# ipro7 register map
Vendor: intelpro; Series: BTBLE
CPU: ipro7, little endian
Registers are 32-bit, read-write, reset 0x0 unless marked. A register's access mark holds for its fields unless they carry their own. Offsets are from the block's base; [hi:lo] are bit positions.

## OSD_BLEND
Base 0x30046000
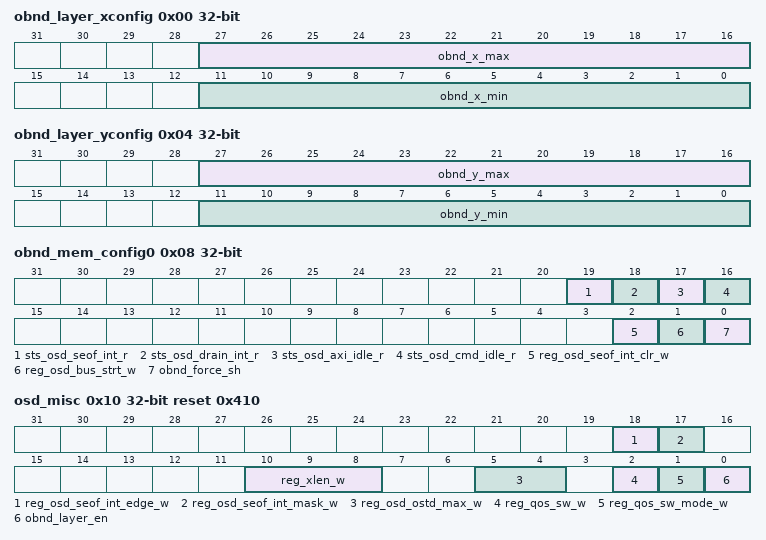
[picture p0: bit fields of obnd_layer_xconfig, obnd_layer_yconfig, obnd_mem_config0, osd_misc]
0x00 obnd_layer_xconfig
  [27:16] obnd_x_max — Start X point of blend layer
  [11:0] obnd_x_min — End X point of blend layer
0x04 obnd_layer_yconfig
  [27:16] obnd_y_max — Start Y point of blend layer
  [11:0] obnd_y_min — End Y point of blend layer
0x08 obnd_mem_config0 (reset mask 0xFFF0FFFF)
  [19] sts_osd_seof_int_r ro — Osd s/e-of status
  [18] sts_osd_drain_int_r ro — Osd drain status
  [17] sts_osd_axi_idle_r ro — AXI Status
  [16] sts_osd_cmd_idle_r ro — Layer command status
  [2] reg_osd_seof_int_clr_w wo — OSD seof interrupt clear
  [1] reg_osd_bus_strt_w wo — Bus start
  [0] obnd_force_sh wo — Force shadow
0x10 osd_misc reset 0x410
  [18] reg_osd_seof_int_edge_w — OSD seof interrupt edge select 1'b0 : Negedge / 1'b1 : Posedge
  [17] reg_osd_seof_int_mask_w — OSD seof interrupt mask
  [10:8] reg_xlen_w — Maximum arlen burst length max(arlen) = 1<<(reg_xlen+1) - 1
  [5:4] reg_osd_ostd_max_w — Outstanding maximum setting
  [2] reg_qos_sw_w — AXI Qos software mode value
  [1] reg_qos_sw_mode_w — AXI QoS software mode enable
  [0] obnd_layer_en — Enable blend layer
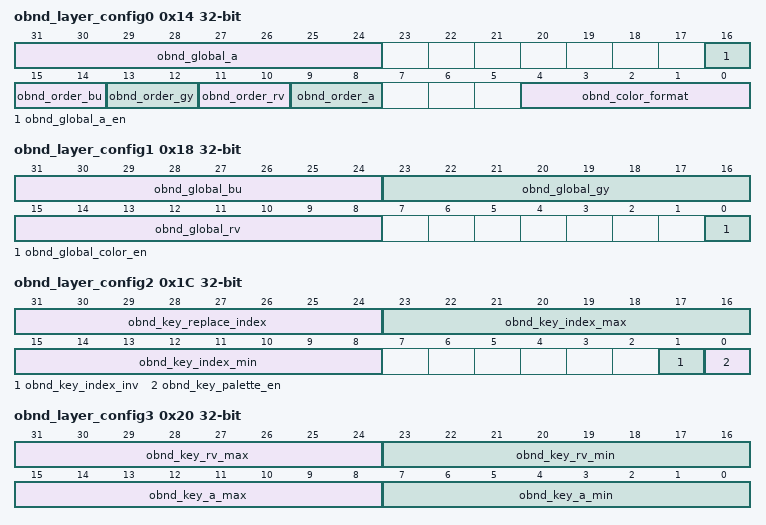
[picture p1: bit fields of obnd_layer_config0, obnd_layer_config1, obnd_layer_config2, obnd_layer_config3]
0x14 obnd_layer_config0
  [31:24] obnd_global_a — Global alpha. Range:0~255
  [16] obnd_global_a_en — Enable global alpha
  [15:14] obnd_order_bu — Order blue or u of blend data. Range:0~3
  [13:12] obnd_order_gy — Order green or y of blend data. Range:0~3
  [11:10] obnd_order_rv — Order red or v of blend data. Range:0~3
  [9:8] obnd_order_a — Order alpha of blend data. Range:0~3
  [4:0] obnd_color_format — Color format of blend data. Range:0~17 5'd0 : ARGB8888 5'd1 : AYUV8888 5'd2 : ARGB4444 5'd3 : AYUV4444 5'd4 : ARGB1555 5'd5 : AYUV1555 5'd6 : RGB565 5'd7 : YUV655 5'd8 : A8_RGB 5'd9 : A8_YUV 5'd10 : PALETTE_8_BIT_ARGB 5'd11 : PALETTE_8_BIT_AYUV 5'd12 : PALETTE_4_BIT_ARGB 5'd13 : PALETTE_4_BIT_AYUV 5'd14 : PALETTE_2_BIT_ARGB 5'd15 : PALETTE_2_BIT_AYUV 5'd16 : PALETTE_1_BIT_ARGB 5'd17 : PALETTE_1_BIT_AYUV
0x18 obnd_layer_config1
  [31:24] obnd_global_bu — Global blue or u of blend data. Range:0~255
  [23:16] obnd_global_gy — Global green or y of blend data. Range:0~255
  [15:8] obnd_global_rv — Global red or v of blend data. Range:0~255
  [0] obnd_global_color_en — Enable global color of blend layer
0x1C obnd_layer_config2
  [31:24] obnd_key_replace_index — Replace index of Key. Range:0~255
  [23:16] obnd_key_index_max — Max of key index. Range:0~255
  [15:8] obnd_key_index_min — Min of key index. Range:0~255
  [1] obnd_key_index_inv — Invert of key index
  [0] obnd_key_palette_en — Enable key palette
0x20 obnd_layer_config3
  [31:24] obnd_key_rv_max — Max of key red or v. Range:0~255
  [23:16] obnd_key_rv_min — Min of key red or v. Range:0~255
  [15:8] obnd_key_a_max — Max of key alpha. Range:0~255
  [7:0] obnd_key_a_min — Min of key alpha. Range:0~255
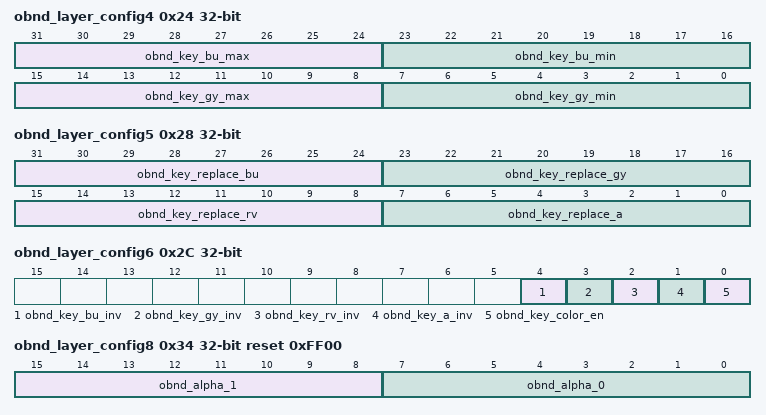
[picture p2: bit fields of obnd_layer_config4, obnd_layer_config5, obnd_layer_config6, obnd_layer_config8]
0x24 obnd_layer_config4
  [31:24] obnd_key_bu_max — Max of key blue or u. Range:0~255
  [23:16] obnd_key_bu_min — Min of key blue or u. Range:0~255
  [15:8] obnd_key_gy_max — Max of key green or y. Range:0~255
  [7:0] obnd_key_gy_min — Min of key green or y. Range:0~255
0x28 obnd_layer_config5
  [31:24] obnd_key_replace_bu — Replace blue or u of Key. Range:0~255
  [23:16] obnd_key_replace_gy — Replace green or y of Key. Range:0~255
  [15:8] obnd_key_replace_rv — Replace red of v of Key. Range:0~255
  [7:0] obnd_key_replace_a — Replace alpha of Key. Range:0~255
0x2C obnd_layer_config6
  [4] obnd_key_bu_inv — Invert of key blue or u
  [3] obnd_key_gy_inv — Invert of key green or y
  [2] obnd_key_rv_inv — Invert of key red or v
  [1] obnd_key_a_inv — Invert of key alpha
  [0] obnd_key_color_en — Enable key color
0x34 obnd_layer_config8 reset 0xFF00
  [15:8] obnd_alpha_1 — ARGB1555, alpha 1 setting
  [7:0] obnd_alpha_0 — ARGB1555, alpha 0 setting
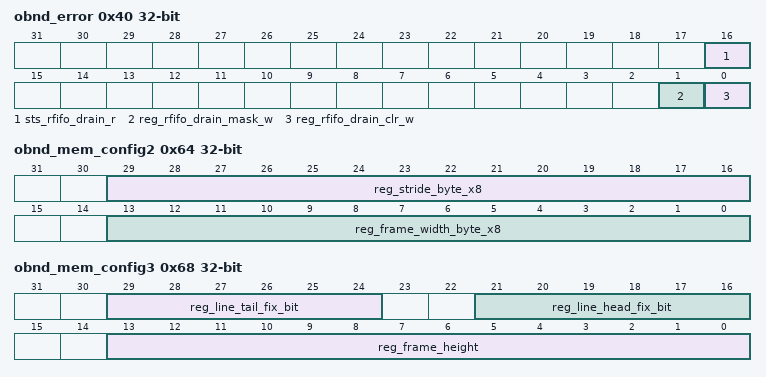
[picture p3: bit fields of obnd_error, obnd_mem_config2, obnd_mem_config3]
0x40 obnd_error (reset mask 0xFFFEFFFF)
  [16] sts_rfifo_drain_r ro — FIFI Drain Status
  [1] reg_rfifo_drain_mask_w — FIFO Drain Mask
  [0] reg_rfifo_drain_clr_w wo — FIFO Drain Clear
0x44 obnd_sh reset 0x1000
  [31:0] obnd_layer_mem_req_cnt — The number of cycle in V-Blanking to shadow config parameters and get memory blend data
0x60 obnd_mem_config1
  [31:0] reg_addr_start — Memory address to get blend layer data
0x64 obnd_mem_config2
  [29:16] reg_stride_byte_x8 — Frame stride width (Unit - 8byte)
  [13:0] reg_frame_width_byte_x8 — Frame valid width (Unit - 8byte)
0x68 obnd_mem_config3
  [29:24] reg_line_tail_fix_bit — OSD image line tail fix bit Image will ignore "reg_line_head_fix_bit" bit in each line tail
  [21:16] reg_line_head_fix_bit — OSD image line head fix bit Image will ignore "reg_line_head_fix_bit" bit in each line head
  [13:0] reg_frame_height — Frame valid height
